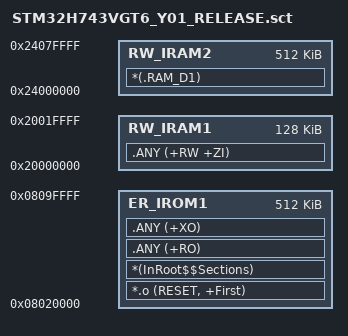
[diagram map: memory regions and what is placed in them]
; *************************************************************
; *** Scatter-Loading Description File generated by uVision ***
; *************************************************************

LR_IROM1 0x08020000 0x00080000  {    ; load region size_region
  ER_IROM1 0x08020000 0x00080000  {  ; load address = execution address
   *.o (RESET, +First)
   *(InRoot$$Sections)
   .ANY (+RO)
   .ANY (+XO)
  }
  RW_IRAM1 0x20000000 0x00020000  {  ; RW data - DTCMRAM (128KB)
   .ANY (+RW +ZI)
  }
  RW_IRAM2 0x24000000 0x00080000  {  ; RAM D1 - AXI SRAM (512KB)
   *(.RAM_D1)
  }
  ;RW_IRAM3 0x30000000 0x00048000  {  ; RAM D2 - AHB SRAM 1~3 (288KB)
  ; *(.RAM_D2)
  ;}
  ;RW_IRAM4 0x38000000 0x00010000  {  ; RAM D3 - AHB SRAM Domain4 (64KB)
  ; *(.RAM_D3)
  ;}
  ;RW_IRAM5 0x00000000 0x00010000  {  ; RW data - ITCMRAM (64KB)
  ;}
}

